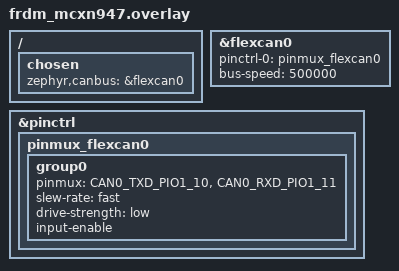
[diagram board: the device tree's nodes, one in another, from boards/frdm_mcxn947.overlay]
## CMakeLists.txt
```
cmake_minimum_required(VERSION 3.20.0)

find_package(Zephyr REQUIRED HINTS $ENV{ZEPHYR_BASE})
project(CAN_BUS_Demo)

target_sources(app PRIVATE src/main.c)
```

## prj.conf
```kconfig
CONFIG_GPIO=y
CONFIG_CAN=y
CONFIG_CAN_INIT_PRIORITY=80

# Logging / console
CONFIG_PRINTK=y
CONFIG_LOG=y
CONFIG_LOG_MODE_DEFERRED=y
CONFIG_LOG_DEFAULT_LEVEL=3
CONFIG_SERIAL=y
CONFIG_CONSOLE=y
CONFIG_UART_CONSOLE=y
```

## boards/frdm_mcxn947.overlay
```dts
/ {
    chosen {
        zephyr,canbus = &flexcan0;   /* or &flexcan1, see zephyr.dts */
    };
};

&flexcan0 {
	pinctrl-0 = <&pinmux_flexcan0>;
    bus-speed = <500000>;   /* must match your adapter's bitrate */
};

&pinctrl{
	pinmux_flexcan0: pinmux_flexcan0 {
		group0 {
			pinmux = <CAN0_TXD_PIO1_10>,
				<CAN0_RXD_PIO1_11>;
			slew-rate = "fast";
			drive-strength = "low";
			input-enable;
		};
	};
};
```

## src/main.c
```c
#include <zephyr/kernel.h>
#include <zephyr/device.h>
#include <zephyr/drivers/can.h>
#include <zephyr/sys/printk.h>

#if DT_HAS_CHOSEN(zephyr_canbus)
#define CAN_NODE DT_CHOSEN(zephyr_canbus)
#else
#define CAN_NODE DT_NODELABEL(can0)
#endif

static const struct device *const can_dev = DEVICE_DT_GET(CAN_NODE);

static void rx_cb(const struct device *dev, struct can_frame *frame, void *user_data)
{
    ARG_UNUSED(dev);
    ARG_UNUSED(user_data);

    bool ext = (frame->flags & CAN_FRAME_IDE) != 0;
    printk("CAN RX: id=0x%08x %s dlc=%d data=",
           frame->id, ext ? "EXT" : "STD", frame->dlc);
    for (int i = 0; i < frame->dlc; i++) {
        printk("%02X", frame->data[i]);
    }
    printk("\n");
}

void main(void)
{
    if (!device_is_ready(can_dev)) {
        printk("CAN device not ready\n");
        return;
    }

    /* Bitrate from overlay is enough; this is optional override: */
    if (can_set_bitrate(can_dev, 500000)) {
        printk("Failed to set bitrate\n");
        return;
    }

    if (can_start(can_dev)) {
        printk("Failed to start CAN\n");
        return;
    }

    /* Accept ALL standard frames */
    struct can_filter flt = {
        .id = 0x000,
        .mask = 0x000,     /* mask 0 -> don’t care bits */
        .flags = 0         /* standard (11-bit) frames */
    };
    int fid = can_add_rx_filter(can_dev, rx_cb, NULL, &flt);
    if (fid < 0) {
        printk("Add STD filter failed: %d\n", fid);
    }

    /* Accept ALL extended frames */
    flt.flags = CAN_FILTER_IDE;   /* match IDE=1 (29-bit) */
    fid = can_add_rx_filter(can_dev, rx_cb, NULL, &flt);
    if (fid < 0) {
        printk("Add EXT filter failed: %d\n", fid);
    }

    printk("CAN up. Listening…\n");

    /* Optional: send a test frame every 1s */
    while (1) {
        struct can_frame tx = {
            .id = 0x123,
            .dlc = 4,
            .flags = 0,               /* standard frame */
            .data = {0xDE, 0xAD, 0xBE, 0xEF},
        };
        int ret = can_send(can_dev, &tx, K_MSEC(100), NULL, NULL);
        if (ret) {
            printk("TX err %d\n", ret);
        }
        k_sleep(K_SECONDS(1));
    }
}
```
